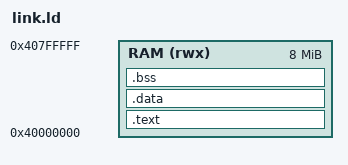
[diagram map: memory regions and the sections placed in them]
ENTRY(_start)
MEMORY { RAM (rwx) : ORIGIN = 0x40000000, LENGTH = 8M }
SECTIONS {
  .text : { *(.text.start) *(.text*) *(.rodata*) *(.srodata*) } > RAM
  .data : { *(.data*) *(.sdata*) } > RAM
  .bss  : { __bss_start = .; *(.bss*) *(.sbss*) *(COMMON) __bss_end = .; } > RAM
  . = ALIGN(16); . += 0x8000; __stack_top = .;
}
